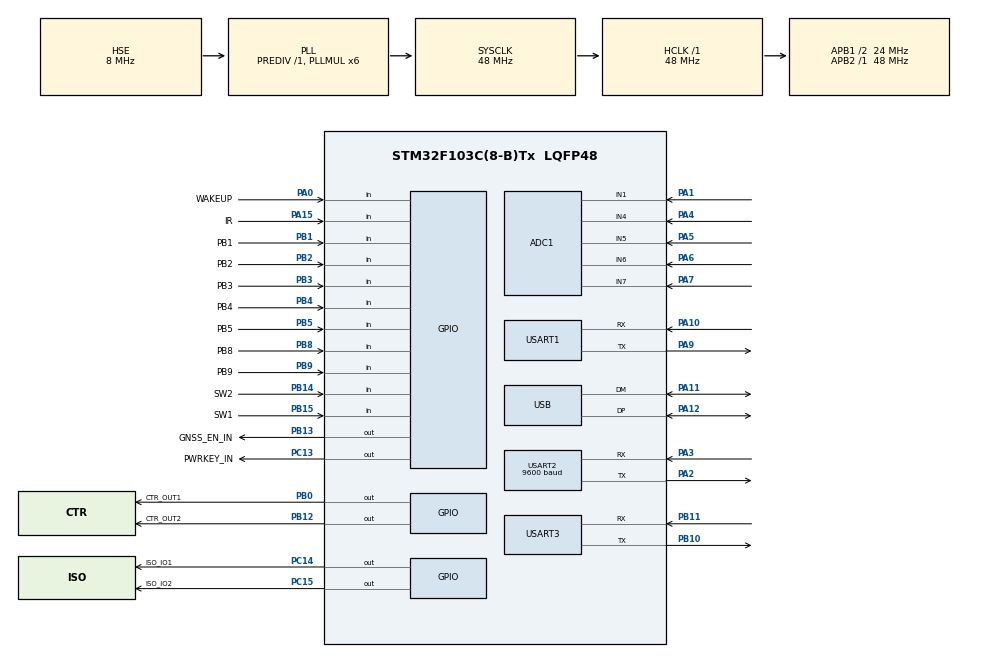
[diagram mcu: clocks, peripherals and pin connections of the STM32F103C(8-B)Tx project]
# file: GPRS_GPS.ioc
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ADC1.Channel-0\#ChannelRegularConversion=ADC_CHANNEL_1
ADC1.NbrOfConversionFlag=1
ADC1.Rank-0\#ChannelRegularConversion=1
ADC1.SamplingTime-0\#ChannelRegularConversion=ADC_SAMPLETIME_1CYCLE_5
ADC1.master=1
Dma.Request0=USART1_RX
Dma.USART1_RX.0.Direction=DMA_PERIPH_TO_MEMORY
Dma.USART1_RX.0.Instance=DMA1_Channel5
Dma.USART1_RX.0.MemDataAlignment=DMA_MDATAALIGN_BYTE
Dma.USART1_RX.0.MemInc=DMA_MINC_ENABLE
Dma.USART1_RX.0.Mode=DMA_NORMAL
Dma.USART1_RX.0.PeriphDataAlignment=DMA_PDATAALIGN_BYTE
Dma.USART1_RX.0.PeriphInc=DMA_PINC_DISABLE
Dma.USART1_RX.0.Priority=DMA_PRIORITY_LOW
Mcu.Family=STM32F1
Mcu.Name=STM32F103C(8-B)Tx
Mcu.Package=LQFP48
NVIC.DMA1_Channel5_IRQn=true\:0\:0\:false\:false\:true\:false\:true
NVIC.PriorityGroup=NVIC_PRIORITYGROUP_4
NVIC.USART1_IRQn=true\:0\:0\:false\:false\:true\:true\:true
NVIC.USB_LP_CAN1_RX0_IRQn=true\:0\:0\:false\:false\:true\:false\:true
PA0-WKUP.GPIO_Label=WAKEUP
PA0-WKUP.Signal=GPIO_Input
PA1.Signal=ADCx_IN1
PA10.Mode=Asynchronous
PA10.Signal=USART1_RX
PA11.Mode=Device
PA11.Signal=USB_DM
PA12.Mode=Device
PA12.Signal=USB_DP
PA15.GPIO_Label=IR
PA15.Signal=GPIO_Input
PA2.Mode=Asynchronous
PA2.Signal=USART2_TX
PA3.Mode=Asynchronous
PA3.Signal=USART2_RX
PA4.Signal=ADCx_IN4
PA5.Signal=ADCx_IN5
PA6.Signal=ADCx_IN6
PA7.Signal=ADCx_IN7
PA8.Signal=S_TIM1_CH1
PA9.Mode=Asynchronous
PA9.Signal=USART1_TX
PB0.GPIO_Label=CTR_OUT1
PB0.Signal=GPIO_Output
PB1.GPIO_Label=PB1
PB1.Signal=GPIO_Input
PB10.Mode=Asynchronous
PB10.Signal=USART3_TX
PB11.Mode=Asynchronous
PB11.Signal=USART3_RX
PB12.GPIO_Label=CTR_OUT2
PB12.Signal=GPIO_Output
PB13.GPIO_Label=GNSS_EN_IN
PB13.Signal=GPIO_Output
PB14.GPIO_Label=SW2
PB14.Signal=GPIO_Input
PB15.GPIO_Label=SW1
PB15.Signal=GPIO_Input
PB2.GPIO_Label=PB2
PB2.Signal=GPIO_Input
PB3.GPIO_Label=PB3
PB3.Signal=GPIO_Input
PB4.GPIO_Label=PB4
PB4.Signal=GPIO_Input
PB5.GPIO_Label=PB5
PB5.Signal=GPIO_Input
PB6.Signal=I2C1_SCL
PB7.Signal=I2C1_SDA
PB8.GPIO_Label=PB8
PB8.Signal=GPIO_Input
PB9.GPIO_Label=PB9
PB9.Signal=GPIO_Input
PC13-TAMPER-RTC.GPIO_Label=PWRKEY_IN
PC13-TAMPER-RTC.Signal=GPIO_Output
PC14-OSC32_IN.GPIO_Label=ISO_IO1
PC14-OSC32_IN.Signal=GPIO_Output
PC15-OSC32_OUT.GPIO_Label=ISO_IO2
PC15-OSC32_OUT.Signal=GPIO_Output
PD0-OSC_IN.Mode=HSE-External-Oscillator
PD0-OSC_IN.Signal=RCC_OSC_IN
PD1-OSC_OUT.Mode=HSE-External-Oscillator
PD1-OSC_OUT.Signal=RCC_OSC_OUT
ProjectManager.HeapSize=0x200
ProjectManager.StackSize=0x400
ProjectManager.TargetToolchain=MDK-ARM V5.27
RCC.ADCPresc=RCC_ADCPCLK2_DIV4
RCC.AHBFreq_Value=48000000
RCC.APB1CLKDivider=RCC_HCLK_DIV2
RCC.APB1Freq_Value=24000000
RCC.APB1TimFreq_Value=48000000
RCC.APB2Freq_Value=48000000
RCC.APB2TimFreq_Value=48000000
RCC.HCLKFreq_Value=48000000
RCC.PLLMUL=RCC_PLL_MUL6
RCC.SYSCLKFreq_VALUE=48000000
RCC.SYSCLKSource=RCC_SYSCLKSOURCE_PLLCLK
RCC.USBFreq_Value=48000000
SH.ADCx_IN1.0=ADC1_IN1,IN1
SH.ADCx_IN4.0=ADC1_IN4,IN4
SH.ADCx_IN5.0=ADC1_IN5,IN5
SH.ADCx_IN6.0=ADC1_IN6,IN6
SH.ADCx_IN7.0=ADC1_IN7,IN7
SH.S_TIM1_CH1.0=TIM1_CH1
USART1.VirtualMode=VM_ASYNC
USART2.BaudRate=9600
USART2.VirtualMode=VM_ASYNC
USART3.VirtualMode=VM_ASYNC
USB_DEVICE.CLASS_NAME_FS=CDC
USB_DEVICE.VirtualMode=Cdc
USB_DEVICE.VirtualModeFS=Cdc_FS
VP_SYS_VS_ND.Mode=No_Debug
VP_USB_DEVICE_VS_USB_DEVICE_CDC_FS.Mode=CDC_FS
board=custom

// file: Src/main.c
/* USER CODE BEGIN Header */
/**
  ******************************************************************************
  * @file           : main.c
  * @brief          : Main program body
  ******************************************************************************
  * @attention
  *
  * <h2><center>&copy; Copyright (c) 2020 STMicroelectronics.
  * All rights reserved.</center></h2>
  *
  * This software component is licensed by ST under Ultimate Liberty license
  * SLA0044, the "License"; You may not use this file except in compliance with
  * the License. You may obtain a copy of the License at:
  *                             www.st.com/SLA0044
  *
  ******************************************************************************
  */
/* USER CODE END Header */

#include "main.h"
#include "usb_device.h"

ADC_HandleTypeDef hadc1;

UART_HandleTypeDef huart1;
UART_HandleTypeDef huart2;
UART_HandleTypeDef huart3;
DMA_HandleTypeDef hdma_usart1_rx;

void SystemClock_Config(void);
static void MX_GPIO_Init(void);
static void MX_DMA_Init(void);
static void MX_ADC1_Init(void);
static void MX_USART1_UART_Init(void);
static void MX_USART2_UART_Init(void);
static void MX_USART3_UART_Init(void);

/* USER CODE BEGIN 0 */
int fputc(int ch, FILE *f)

{
	HAL_UART_Transmit(&huart3,(uint8_t *)ch,10,10);
	return ch;
}
#pragma import(__use_no_semihosting)

int _sys_exit(int x)

{

x = x;

}

struct __FILE

{

int handle;

};

FILE __stdout;
/* USER CODE END 0 */

int main(void)
{

  /* MCU Configuration--------------------------------------------------------*/

  /* Reset of all peripherals, Initializes the Flash interface and the Systick. */
  HAL_Init();

  /* Configure the system clock */
  SystemClock_Config();

  /* Initialize all configured peripherals */
  MX_GPIO_Init();
  MX_DMA_Init();
  MX_ADC1_Init();
  MX_USART1_UART_Init();
  MX_USART2_UART_Init();
  MX_USART3_UART_Init();
  MX_USB_DEVICE_Init();

  /* Infinite loop */
  while (1)
  {

  }
}

void SystemClock_Config(void)
{
  RCC_OscInitTypeDef RCC_OscInitStruct = {0};
  RCC_ClkInitTypeDef RCC_ClkInitStruct = {0};
  RCC_PeriphCLKInitTypeDef PeriphClkInit = {0};

  /** Initializes the CPU, AHB and APB busses clocks
  */
  RCC_OscInitStruct.OscillatorType = RCC_OSCILLATORTYPE_HSE;
  RCC_OscInitStruct.HSEState = RCC_HSE_ON;
  RCC_OscInitStruct.HSEPredivValue = RCC_HSE_PREDIV_DIV1;
  RCC_OscInitStruct.HSIState = RCC_HSI_ON;
  RCC_OscInitStruct.PLL.PLLState = RCC_PLL_ON;
  RCC_OscInitStruct.PLL.PLLSource = RCC_PLLSOURCE_HSE;
  RCC_OscInitStruct.PLL.PLLMUL = RCC_PLL_MUL6;
  if (HAL_RCC_OscConfig(&RCC_OscInitStruct) != HAL_OK)
  {
    Error_Handler();
  }
  /** Initializes the CPU, AHB and APB busses clocks
  */
  RCC_ClkInitStruct.ClockType = RCC_CLOCKTYPE_HCLK|RCC_CLOCKTYPE_SYSCLK
                              |RCC_CLOCKTYPE_PCLK1|RCC_CLOCKTYPE_PCLK2;
  RCC_ClkInitStruct.SYSCLKSource = RCC_SYSCLKSOURCE_PLLCLK;
  RCC_ClkInitStruct.AHBCLKDivider = RCC_SYSCLK_DIV1;
  RCC_ClkInitStruct.APB1CLKDivider = RCC_HCLK_DIV2;
  RCC_ClkInitStruct.APB2CLKDivider = RCC_HCLK_DIV1;

  if (HAL_RCC_ClockConfig(&RCC_ClkInitStruct, FLASH_LATENCY_1) != HAL_OK)
  {
    Error_Handler();
  }
  PeriphClkInit.PeriphClockSelection = RCC_PERIPHCLK_ADC|RCC_PERIPHCLK_USB;
  PeriphClkInit.AdcClockSelection = RCC_ADCPCLK2_DIV4;
  PeriphClkInit.UsbClockSelection = RCC_USBCLKSOURCE_PLL;
  if (HAL_RCCEx_PeriphCLKConfig(&PeriphClkInit) != HAL_OK)
  {
    Error_Handler();
  }
}

static void MX_ADC1_Init(void)
{

  ADC_ChannelConfTypeDef sConfig = {0};

  /** Common config
  */
  hadc1.Instance = ADC1;
  hadc1.Init.ScanConvMode = ADC_SCAN_DISABLE;
  hadc1.Init.ContinuousConvMode = DISABLE;
  hadc1.Init.DiscontinuousConvMode = DISABLE;
  hadc1.Init.ExternalTrigConv = ADC_SOFTWARE_START;
  hadc1.Init.DataAlign = ADC_DATAALIGN_RIGHT;
  hadc1.Init.NbrOfConversion = 1;
  if (HAL_ADC_Init(&hadc1) != HAL_OK)
  {
    Error_Handler();
  }
  /** Configure Regular Channel
  */
  sConfig.Channel = ADC_CHANNEL_1;
  sConfig.Rank = ADC_REGULAR_RANK_1;
  sConfig.SamplingTime = ADC_SAMPLETIME_1CYCLE_5;
  if (HAL_ADC_ConfigChannel(&hadc1, &sConfig) != HAL_OK)
  {
    Error_Handler();
  }

}

static void MX_USART1_UART_Init(void)
{

  huart1.Instance = USART1;
  huart1.Init.BaudRate = 115200;
  huart1.Init.WordLength = UART_WORDLENGTH_8B;
  huart1.Init.StopBits = UART_STOPBITS_1;
  huart1.Init.Parity = UART_PARITY_NONE;
  huart1.Init.Mode = UART_MODE_TX_RX;
  huart1.Init.HwFlowCtl = UART_HWCONTROL_NONE;
  huart1.Init.OverSampling = UART_OVERSAMPLING_16;
  if (HAL_UART_Init(&huart1) != HAL_OK)
  {
    Error_Handler();
  }

}

static void MX_USART2_UART_Init(void)
{

  huart2.Instance = USART2;
  huart2.Init.BaudRate = 9600;
  huart2.Init.WordLength = UART_WORDLENGTH_8B;
  huart2.Init.StopBits = UART_STOPBITS_1;
  huart2.Init.Parity = UART_PARITY_NONE;
  huart2.Init.Mode = UART_MODE_TX_RX;
  huart2.Init.HwFlowCtl = UART_HWCONTROL_NONE;
  huart2.Init.OverSampling = UART_OVERSAMPLING_16;
  if (HAL_UART_Init(&huart2) != HAL_OK)
  {
    Error_Handler();
  }

}

static void MX_USART3_UART_Init(void)
{

  huart3.Instance = USART3;
  huart3.Init.BaudRate = 115200;
  huart3.Init.WordLength = UART_WORDLENGTH_8B;
  huart3.Init.StopBits = UART_STOPBITS_1;
  huart3.Init.Parity = UART_PARITY_NONE;
  huart3.Init.Mode = UART_MODE_TX_RX;
  huart3.Init.HwFlowCtl = UART_HWCONTROL_NONE;
  huart3.Init.OverSampling = UART_OVERSAMPLING_16;
  if (HAL_UART_Init(&huart3) != HAL_OK)
  {
    Error_Handler();
  }

}

static void MX_DMA_Init(void)
{

  /* DMA controller clock enable */
  __HAL_RCC_DMA1_CLK_ENABLE();

  /* DMA interrupt init */
  /* DMA1_Channel5_IRQn interrupt configuration */
  HAL_NVIC_SetPriority(DMA1_Channel5_IRQn, 0, 0);
  HAL_NVIC_EnableIRQ(DMA1_Channel5_IRQn);

}

static void MX_GPIO_Init(void)
{
  GPIO_InitTypeDef GPIO_InitStruct = {0};

  /* GPIO Ports Clock Enable */
  __HAL_RCC_GPIOC_CLK_ENABLE();
  __HAL_RCC_GPIOD_CLK_ENABLE();
  __HAL_RCC_GPIOA_CLK_ENABLE();
  __HAL_RCC_GPIOB_CLK_ENABLE();

  /*Configure GPIO pin Output Level */
  HAL_GPIO_WritePin(GPIOC, PWRKEY_IN_Pin|ISO_IO1_Pin|ISO_IO2_Pin, GPIO_PIN_RESET);

  /*Configure GPIO pin Output Level */
  HAL_GPIO_WritePin(GPIOB, CTR_OUT1_Pin|CTR_OUT2_Pin|GNSS_EN_IN_Pin, GPIO_PIN_RESET);

  /*Configure GPIO pins : PWRKEY_IN_Pin ISO_IO1_Pin ISO_IO2_Pin */
  GPIO_InitStruct.Pin = PWRKEY_IN_Pin|ISO_IO1_Pin|ISO_IO2_Pin;
  GPIO_InitStruct.Mode = GPIO_MODE_OUTPUT_PP;
  GPIO_InitStruct.Pull = GPIO_NOPULL;
  GPIO_InitStruct.Speed = GPIO_SPEED_FREQ_LOW;
  HAL_GPIO_Init(GPIOC, &GPIO_InitStruct);

  /*Configure GPIO pins : WAKEUP_Pin IR_Pin */
  GPIO_InitStruct.Pin = WAKEUP_Pin|IR_Pin;
  GPIO_InitStruct.Mode = GPIO_MODE_INPUT;
  GPIO_InitStruct.Pull = GPIO_NOPULL;
  HAL_GPIO_Init(GPIOA, &GPIO_InitStruct);

  /*Configure GPIO pins : CTR_OUT1_Pin CTR_OUT2_Pin GNSS_EN_IN_Pin */
  GPIO_InitStruct.Pin = CTR_OUT1_Pin|CTR_OUT2_Pin|GNSS_EN_IN_Pin;
  GPIO_InitStruct.Mode = GPIO_MODE_OUTPUT_PP;
  GPIO_InitStruct.Pull = GPIO_NOPULL;
  GPIO_InitStruct.Speed = GPIO_SPEED_FREQ_LOW;
  HAL_GPIO_Init(GPIOB, &GPIO_InitStruct);

  /*Configure GPIO pins : PB1_Pin PB2_Pin SW2_Pin SW1_Pin
                           PB3_Pin PB4_Pin PB5_Pin PB8_Pin
                           PB9_Pin */
  GPIO_InitStruct.Pin = PB1_Pin|PB2_Pin|SW2_Pin|SW1_Pin
                          |PB3_Pin|PB4_Pin|PB5_Pin|PB8_Pin
                          |PB9_Pin;
  GPIO_InitStruct.Mode = GPIO_MODE_INPUT;
  GPIO_InitStruct.Pull = GPIO_NOPULL;
  HAL_GPIO_Init(GPIOB, &GPIO_InitStruct);

  /*Configure GPIO pin : PA8 */
  GPIO_InitStruct.Pin = GPIO_PIN_8;
  GPIO_InitStruct.Mode = GPIO_MODE_AF_PP;
  GPIO_InitStruct.Speed = GPIO_SPEED_FREQ_LOW;
  HAL_GPIO_Init(GPIOA, &GPIO_InitStruct);

  /*Configure GPIO pins : PB6 PB7 */
  GPIO_InitStruct.Pin = GPIO_PIN_6|GPIO_PIN_7;
  GPIO_InitStruct.Mode = GPIO_MODE_AF_OD;
  GPIO_InitStruct.Speed = GPIO_SPEED_FREQ_HIGH;
  HAL_GPIO_Init(GPIOB, &GPIO_InitStruct);

}

void Error_Handler(void)
{
}

/************************ (C) COPYRIGHT STMicroelectronics *****END OF FILE****/
